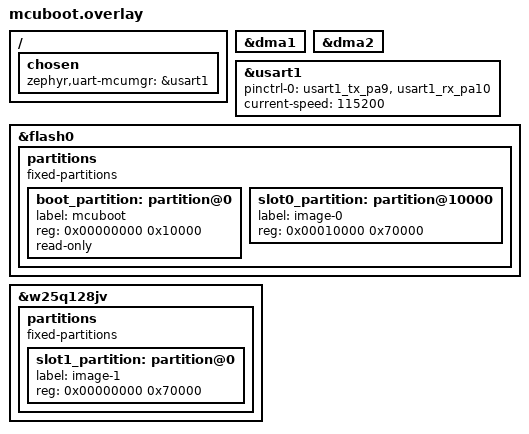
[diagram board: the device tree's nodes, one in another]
/*
 * mcuboot.overlay — MCUboot 引导程序设备树覆盖 (NOR Flash 方案, 无按键入口)
 *
 * 功能:
 *   1. 启用 USART1 (PA9/PA10) 作为 mcumgr 串口恢复通道（应急恢复）
 *   2. 定义 Flash 分区 — slot1 在外部 NOR Flash (W25Q128), indirect 模式
 *
 * 升级流程（无按键）:
 *   应用层 mcumgr 上传 .signed.bin → 写入 slot1 (NOR Flash) → 标记 pending →
 *   重启 → MCUboot 检测 pending 镜像 → slot1→slot0 覆写 → 启动新固件
 *
 * Flash 布局:
 *   内部 Flash:  boot (64KB) + slot0 (448KB)
 *   外部 NOR:    slot1 (448KB), QSPI indirect 模式（不开 MEMMAP）
 */

/ {
	chosen {
		zephyr,uart-mcumgr = &usart1;
	};
};

/* [DMA] QSPI NOR Flash 依赖 DMA 进行读写传输 */
&dma1 {
	status = "okay";
};

&dma2 {
	status = "okay";
};

/* USART1: PA9(TX) + PA10(RX), 115200 */
&usart1 {
	pinctrl-0 = <&usart1_tx_pa9 &usart1_rx_pa10>;
	pinctrl-names = "default";
	current-speed = <115200>;
	status = "okay";
};

/*
 * [Flash 分区] — 必须与应用程序 overlay 完全一致
 * 内部 Flash: boot (64KB) + slot0 (448KB)
 */
&flash0 {
	partitions {
		compatible = "fixed-partitions";
		#address-cells = <1>;
		#size-cells = <1>;

		boot_partition: partition@0 {
			label = "mcuboot";
			reg = <0x00000000 0x10000>;
			read-only;
		};

		slot0_partition: partition@10000 {
			label = "image-0";
			reg = <0x00010000 0x70000>;
		};
	};
};

/* ★ 外部 NOR Flash W25Q128: slot1 (448KB) */
&w25q128jv {
	partitions {
		compatible = "fixed-partitions";
		#address-cells = <1>;
		#size-cells = <1>;

		slot1_partition: partition@0 {
			label = "image-1";
			reg = <0x00000000 0x70000>;
		};
	};
};
